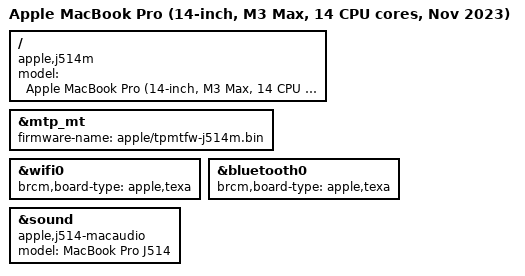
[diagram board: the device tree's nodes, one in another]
// SPDX-License-Identifier: GPL-2.0+ OR MIT
/*
 * MacBook Pro (14-inch, M3 Max, 14 CPU cores, Nov 2023)
 *
 * target-type: J514m
 *
 * Copyright The Asahi Linux Contributors
 */

/dts-v1/;

#include "t6034.dtsi"
#include "t603x-j514-j516.dtsi"

/ {
	compatible = "apple,j514m", "apple,t6034", "apple,arm-platform";
	model = "Apple MacBook Pro (14-inch, M3 Max, 14 CPU cores, Nov 2023)";
};

&mtp_mt {
	firmware-name = "apple/tpmtfw-j514m.bin";
};

&wifi0 {
	brcm,board-type = "apple,texa";
};

&bluetooth0 {
	brcm,board-type = "apple,texa";
};

&sound {
	compatible = "apple,j514-macaudio", "apple,j314-macaudio", "apple,macaudio";
	model = "MacBook Pro J514";
};
